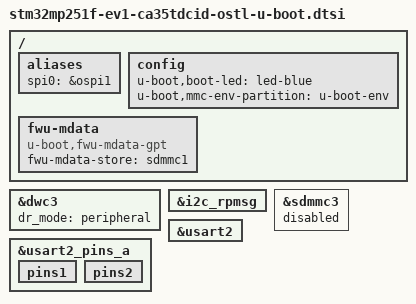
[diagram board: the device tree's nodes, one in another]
// SPDX-License-Identifier: (GPL-2.0-only OR BSD-3-Clause)
/*
 * Copyright (C) STMicroelectronics 2023 - All Rights Reserved
 */

#include "stm32mp25-u-boot.dtsi"

/ {
	aliases {
		spi0 = &ospi1;
	};

	config {
		u-boot,boot-led = "led-blue";
		u-boot,mmc-env-partition = "u-boot-env";
	};

	fwu-mdata {
		compatible = "u-boot,fwu-mdata-gpt";
		fwu-mdata-store = <&sdmmc1>;
	};
};

&dwc3 {
	dr_mode = "peripheral";
	/delete-node/ port;
};

&i2c_rpmsg {
       /delete-node/ typec@35;
};

&sdmmc3 {
	status = "disabled";
};

&usart2 {
	bootph-all;
};

&usart2_pins_a {
	bootph-all;
	pins1 {
		bootph-all;
	};
	pins2 {
		bootph-all;
	};
};
